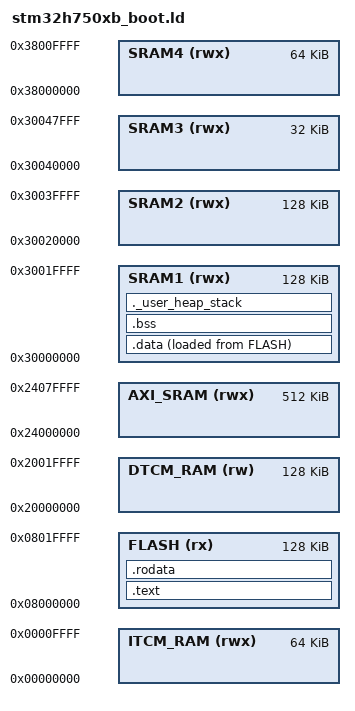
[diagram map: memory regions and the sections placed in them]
/* Entry Point */
ENTRY(Reset_Handler)

/* Memories definition */
MEMORY
{
    ITCM_RAM    (rwx) : ORIGIN = 0x00000000, LENGTH = 64K
    FLASH       (rx)  : ORIGIN = 0x08000000, LENGTH = 128K
    DTCM_RAM    (rw)  : ORIGIN = 0x20000000, LENGTH = 128K
    AXI_SRAM    (rwx) : ORIGIN = 0x24000000, LENGTH = 512K
    SRAM1       (rwx) : ORIGIN = 0x30000000, LENGTH = 128K
    SRAM2       (rwx) : ORIGIN = 0x30020000, LENGTH = 128K
    SRAM3       (rwx) : ORIGIN = 0x30040000, LENGTH = 32K
    SRAM4       (rwx) : ORIGIN = 0x38000000, LENGTH = 64K
}

/* Stack & Heap definitions */
__stack_end__                           = ORIGIN(SRAM1) + LENGTH(SRAM1);
__Min_Heap_Size__                       = 0x200;
__Min_Stack_Size__                      = 0x400;

/* Sections */
SECTIONS
{
    /* The program goes into the .text section */
    .text :
    {
        . = ALIGN(4);
        __text_start__ = .;
        *(.text)
        *(.text*)
        . = ALIGN(4);
        __text_end__ = .;
    } >FLASH

    /* Constant data goes into .rodata section */
    .rodata :
    {
        . = ALIGN(4);
        __rodata_start__ = .;
        *(.rodata)
        *(.rodata*)
        . = ALIGN(4);
        __rodata_end__ = .;
    } >FLASH

    /* Used by the startup to initialize data */
    __data_start_initialize__ = LOADADDR(.data);

    /* Initialized data go into the .data section */
    .data :
    {
        . = ALIGN(4);
        __data_start__ = .;
        *(.data)
        *(.data*)
        . = ALIGN(4);
        __data_end__ = .;
    } >SRAM1 AT> FLASH

    /* Uninitialised data goes into .bss section */
    .bss :
    {
        __bss_start__ = .;
        *(.bss)
        *(.bss*)
        *(COMMON)
        . = ALIGN(4);
        __bss_end__ = .;
    } >SRAM1

    /* Use of the rest of RAM for the stack and heap */
    ._user_heap_stack :
    {
        . = ALIGN(8);
        PROVIDE ( end = . );
        PROVIDE ( _end = . );
        . = . + __Min_Heap_Size__;
        . = . + __Min_Stack_Size__;
        . = ALIGN(8);
    } >SRAM1
}

